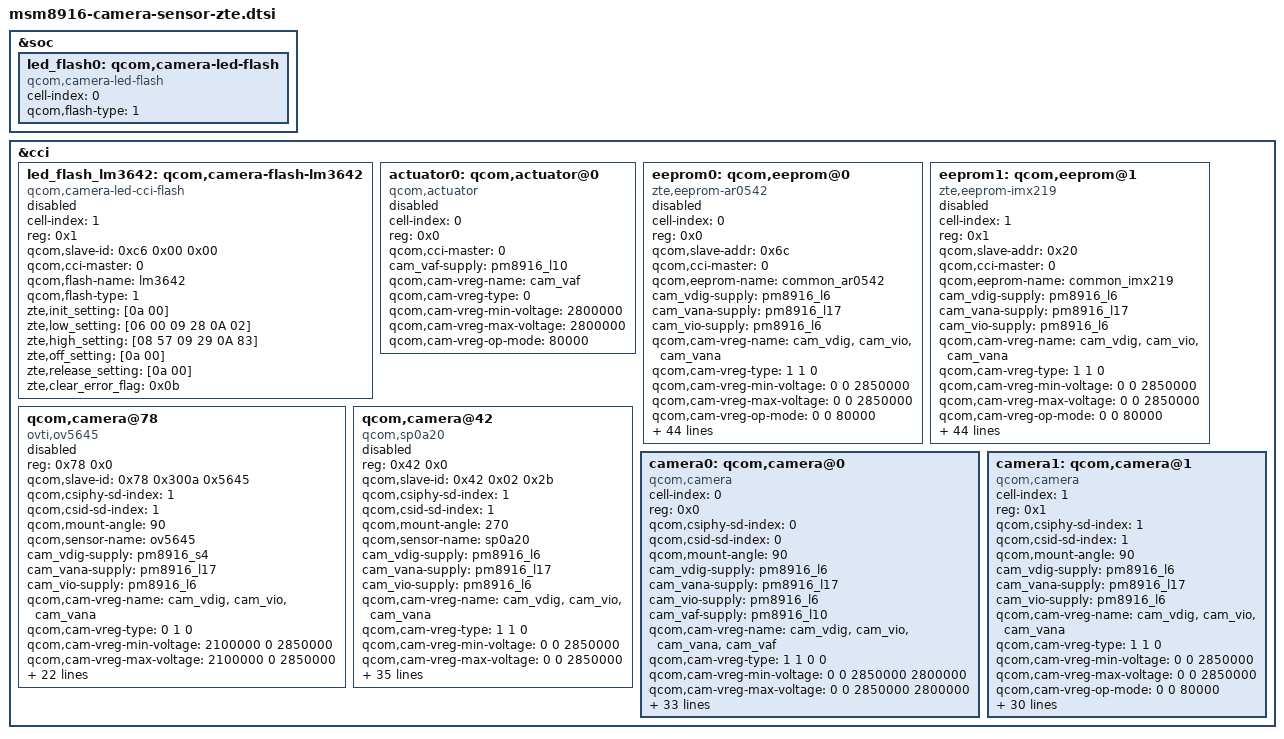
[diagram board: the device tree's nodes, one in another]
/*
 * Copyright (c) 2014, The Linux Foundation. All rights reserved.
 *
 * This program is free software; you can redistribute it and/or modify
 * it under the terms of the GNU General Public License version 2 and
 * only version 2 as published by the Free Software Foundation.
 *
 * This program is distributed in the hope that it will be useful,
 * but WITHOUT ANY WARRANTY; without even the implied warranty of
 * MERCHANTABILITY or FITNESS FOR A PARTICULAR PURPOSE.  See the
 * GNU General Public License for more details.
 */

/*
  * Added for camera sensor platform dtsi file  
  *
  * by ZTE_YCM_20140711 yi.changming 000011
  */
// --->
&soc {
	led_flash0: qcom,camera-led-flash {
		cell-index = <0>;
		compatible = "qcom,camera-led-flash";
		qcom,flash-type = <1>;
	};
};

&cci {


	led_flash_lm3642: qcom,camera-flash-lm3642 {
		cell-index = <1>;
		reg = <0x1>;
		qcom,slave-id = <0xc6 0x00 0x00>;
		compatible = "qcom,camera-led-cci-flash";
		qcom,cci-master = <0>;
		qcom,flash-name = "lm3642";
		qcom,flash-type = <1>;
		zte,init_setting = [0a 00];
		zte,low_setting = [06  00 // torch time, ramp-up time 16ms, ramp-down time 16ms
	 				      09  28   // current control, torch current 140.63mA, flash current 843.75mA
	 				      0A  02];  // enable register, torch mode, strobe pin disabled
		zte,high_setting = [08 57  // flash time, ramp time 1.024ms, time-out time 800ms
	 					09 29   // current control, torch current 140.63mA, flash current 937.5mA
	 					0A 83];  // enable register, flash mode, strobe pin disabled
		zte,off_setting = [0a 00];
		zte,release_setting = [0a 00];
		zte,clear_error_flag = <0x0b>;
		status = "disabled";
	};


	actuator0: qcom,actuator@0 {
		cell-index = <0>;
		reg = <0x0>;
		compatible = "qcom,actuator";
		qcom,cci-master = <0>;
		cam_vaf-supply = <&pm8916_l10>;
		qcom,cam-vreg-name = "cam_vaf";
		qcom,cam-vreg-type = <0>;
		qcom,cam-vreg-min-voltage = <2800000>;
		qcom,cam-vreg-max-voltage = <2800000>;
		qcom,cam-vreg-op-mode = <80000>;
		status = "disabled";
	};

/*
  * Added ar0542 eeprom device node  
  *
  * by ZTE_YCM_20140724 yi.changming 000025
  */
// --->
	eeprom0: qcom,eeprom@0 {
		compatible = "zte,eeprom-ar0542";
		cell-index = <0>;
		reg = <0x0>;
		qcom,slave-addr = <0x6c>;
		qcom,cci-master = <0>;
		qcom,eeprom-name = "common_ar0542";
		cam_vdig-supply = <&pm8916_l6>;
		cam_vana-supply = <&pm8916_l17>;
		cam_vio-supply = <&pm8916_l6>;
		qcom,cam-vreg-name = "cam_vdig", "cam_vio", "cam_vana";
		qcom,cam-vreg-type = <1 1 0 >;
		qcom,cam-vreg-min-voltage = <0 0 2850000>;
		qcom,cam-vreg-max-voltage = <0 0 2850000>;
		qcom,cam-vreg-op-mode = <0 0 80000>;
		pinctrl-names = "cam_default", "cam_suspend";
		pinctrl-0 = <&cam_sensor_mclk0_default
				     &cam_sensor_rear_default
				     &cam_sensor_power_avdd_default
				     &cam_sensor_power_iovdd_default
				     &cam_sensor_power_dvdd_rear_default
				     &cam_sensor_power_dvdd_front_default>;
		pinctrl-1 = <&cam_sensor_mclk0_sleep 
				     &cam_sensor_rear_sleep
				     &cam_sensor_power_avdd_sleep
				     &cam_sensor_power_iovdd_sleep
				     &cam_sensor_power_dvdd_rear_sleep
				     &cam_sensor_power_dvdd_front_sleep>;
		gpios = <&msm_gpio 26 0>,
			<&msm_gpio 35 0>,
			<&msm_gpio 34 0>,
			<&msm_gpio 17 0>,
			<&msm_gpio 121 0>,
			<&msm_gpio 16 0>,
			<&msm_gpio 36 0>;
		qcom,gpio-reset = <1>;
		qcom,gpio-standby = <2>;
		qcom,gpio-vio = <3>;
		qcom,gpio-vdig = <4>;
		qcom,gpio-vana = <5>;
		qcom,gpio-vdig-other = <6>;
		qcom,gpio-req-tbl-num = <0 1 2 3 4 5 6>;
		qcom,gpio-req-tbl-flags = <1 0 0 0 0 0 0>;
		qcom,gpio-req-tbl-label = "CAMIF_MCLK",
			"CAM_RESET1",
			"CAM_STANDBY",
			"CAM_VIO",
			"CAM_VDIG",
			"CAM_VANA",
			"CAM_VDIG_OTHER";
		qcom,cam-power-seq-type = "sensor_gpio",
								     "sensor_gpio",
								     "sensor_gpio",
								     "sensor_gpio",
								     "sensor_gpio",
								     "sensor_clk",
								     "sensor_gpio",
								     "sensor_gpio",
								     "sensor_i2c_mux";
		qcom,cam-power-seq-val = "sensor_gpio_reset",
								   "sensor_gpio_standby",
								    "sensor_gpio_vio",
								    "sensor_gpio_vdig",
								   "sensor_gpio_vana",
								    "sensor_cam_mclk",
								    "sensor_gpio_reset",
								   "sensor_gpio_standby",
								   "none";						 
		qcom,cam-power-seq-cfg-val = < 0 0   1 1 1 23880000  1 1 0>;
		qcom,cam-power-seq-delay =   < 0 10 0 3 3  2              3 3 0>;
		zte,num-blocks = <3>;
		zte,mem0    = <8     0x3802 2 0x0 1 0>;	//id
		zte,mem1    = <212  0x3802 2 0x0 1 0>;  //lsc
		zte,mem2    = <4     0x38d6 2 0x0 1 0>;   //wb
		clocks = <&clock_gcc clk_mclk0_clk_src>,
				<&clock_gcc clk_gcc_camss_mclk0_clk>;
		clock-names = "cam_src_clk", "cam_clk";
		status = "disabled";
		
	};
// <---

	eeprom1: qcom,eeprom@1 {
		compatible = "zte,eeprom-imx219";
		cell-index = <1>;
		reg = <0x1>;
		qcom,slave-addr = <0x20>;
		qcom,cci-master = <0>;
		qcom,eeprom-name = "common_imx219";
		cam_vdig-supply = <&pm8916_l6>;
		cam_vana-supply = <&pm8916_l17>;
		cam_vio-supply = <&pm8916_l6>;
		qcom,cam-vreg-name = "cam_vdig", "cam_vio", "cam_vana";
		qcom,cam-vreg-type = <1 1 0 >;
		qcom,cam-vreg-min-voltage = <0 0 2850000>;
		qcom,cam-vreg-max-voltage = <0 0 2850000>;
		qcom,cam-vreg-op-mode = <0 0 80000>;
		pinctrl-names = "cam_default", "cam_suspend";
		pinctrl-0 = <&cam_sensor_mclk0_default
				     &cam_sensor_rear_default
				     &cam_sensor_power_avdd_default
				     &cam_sensor_power_iovdd_default
				     &cam_sensor_power_dvdd_rear_default
				     &cam_sensor_power_dvdd_front_default>;
		pinctrl-1 = <&cam_sensor_mclk0_sleep 
				     &cam_sensor_rear_sleep
				     &cam_sensor_power_avdd_sleep
				     &cam_sensor_power_iovdd_sleep
				     &cam_sensor_power_dvdd_rear_sleep
				     &cam_sensor_power_dvdd_front_sleep>;
		gpios = <&msm_gpio 26 0>,
			<&msm_gpio 35 0>,
			<&msm_gpio 34 0>,
			<&msm_gpio 17 0>,
			<&msm_gpio 121 0>,
			<&msm_gpio 16 0>,
			<&msm_gpio 36 0>;
		qcom,gpio-reset = <1>;
		qcom,gpio-standby = <2>;
		qcom,gpio-vio = <3>;
		qcom,gpio-vdig = <4>;
		qcom,gpio-vana = <5>;
		qcom,gpio-vdig-other = <6>;
		qcom,gpio-req-tbl-num = <0 1 2 3 4 5 6>;
		qcom,gpio-req-tbl-flags = <1 0 0 0 0 0 0>;
		qcom,gpio-req-tbl-label = "CAMIF_MCLK",
			"CAM_RESET1",
			"CAM_STANDBY",
			"CAM_VIO",
			"CAM_VDIG",
			"CAM_VANA",
			"CAM_VDIG_OTHER";
		qcom,cam-power-seq-type = "sensor_gpio",
								     "sensor_gpio",
								     "sensor_gpio",
								     "sensor_gpio",
								     "sensor_gpio",
								     "sensor_clk",
								     "sensor_gpio",
								     "sensor_gpio",
								     "sensor_i2c_mux";
		qcom,cam-power-seq-val = "sensor_gpio_reset",
								   "sensor_gpio_standby",
								    "sensor_gpio_vio",
								    "sensor_gpio_vdig",
								   "sensor_gpio_vana",
								    "sensor_cam_mclk",
								    "sensor_gpio_reset",
								   "sensor_gpio_standby",
								   "none";						 
		qcom,cam-power-seq-cfg-val = < 0 0   1 1 1 23880000  1 1 0>;
		qcom,cam-power-seq-delay =   < 0 10 0 3 3  2              3 3 0>;
		zte,num-blocks = <3>;
		zte,mem0    = <24     0x3205 2 0x0 1 0>;	//id wb
		zte,mem1    = <5  0x3225 2 0x0 1 0>;  //af
		zte,mem2    = <8  0 2 0x0 1 0>;  //af
		clocks = <&clock_gcc clk_mclk0_clk_src>,
				<&clock_gcc clk_gcc_camss_mclk0_clk>;
		clock-names = "cam_src_clk", "cam_clk";
		status = "disabled";
		
	};

	qcom,camera@78 {
		compatible = "ovti,ov5645";
		reg = <0x78 0x0>;
		qcom,slave-id = <0x78 0x300a 0x5645>;
		qcom,csiphy-sd-index = <1>;
		qcom,csid-sd-index = <1>;
		qcom,mount-angle = <90>;
		qcom,sensor-name = "ov5645";
		cam_vdig-supply = <&pm8916_s4>;
		cam_vana-supply = <&pm8916_l17>;
		cam_vio-supply = <&pm8916_l6>;
		qcom,cam-vreg-name = "cam_vdig", "cam_vio", "cam_vana";
		qcom,cam-vreg-type = <0 1 0>;
		qcom,cam-vreg-min-voltage = <2100000 0 2850000>;
		qcom,cam-vreg-max-voltage = <2100000 0 2850000>;
		qcom,cam-vreg-op-mode = <200000 0 80000>;
		pinctrl-names = "cam_default", "cam_suspend";
		pinctrl-0 = <&cam_sensor_mclk1_default
				&cam_sensor_front_default>;
		pinctrl-1 = <&cam_sensor_mclk1_sleep &cam_sensor_front_sleep>;
		gpios = <&msm_gpio 27 0>,
			<&msm_gpio 28 0>,
			<&msm_gpio 33 0>;
		qcom,gpio-reset = <1>;
		qcom,gpio-standby = <2>;
		qcom,gpio-req-tbl-num = <0 1 2>;
		qcom,gpio-req-tbl-flags = <1 0 0>;
		qcom,gpio-req-tbl-label = "CAMIF_MCLK",
					"CAM_RESET",
					"CAM_STANDBY";
		qcom,gpio-set-tbl-num = <1 1>;
		qcom,gpio-set-tbl-flags = <0 2>;
		qcom,gpio-set-tbl-delay = <1000 4000>;
		qcom,csi-lane-assign = <0x4320>;
		qcom,csi-lane-mask = <0x3>;
		qcom,sensor-position = <1>;
		qcom,sensor-mode = <0>;
		qcom,cci-master = <0>;
		clocks = <&clock_gcc clk_mclk1_clk_src>,
				<&clock_gcc clk_gcc_camss_mclk1_clk>;
		clock-names = "cam_src_clk", "cam_clk";
		status = "disabled";
	};

/*
  * add sp0a20 sensor (kernel)
  * 
  *by ZTE_YCM_20141104 yi.changming 000099
  */
// --->
	qcom,camera@42 {
		compatible = "qcom,sp0a20";
		reg = <0x42 0x0>;
		qcom,slave-id = <0x42 0x02 0x2b>;
		qcom,csiphy-sd-index = <1>;
		qcom,csid-sd-index = <1>;
		qcom,mount-angle = <270>;
		qcom,sensor-name = "sp0a20";
		cam_vdig-supply = <&pm8916_l6>;
		cam_vana-supply = <&pm8916_l17>;
		cam_vio-supply = <&pm8916_l6>;
		qcom,cam-vreg-name = "cam_vdig", "cam_vio", "cam_vana";
		qcom,cam-vreg-type = <1 1 0>;
		qcom,cam-vreg-min-voltage = <0 0 2850000>;
		qcom,cam-vreg-max-voltage = <0 0 2850000>;
		qcom,cam-vreg-op-mode = <0 0 80000>;
		pinctrl-names = "cam_default", "cam_suspend";
		pinctrl-0 = <&cam_sensor_mclk1_default 
				     &cam_sensor_front_default 
				     &cam_sensor_power_avdd_default
				     &cam_sensor_power_iovdd_default
				     &cam_sensor_power_dvdd_rear_default
				     &cam_sensor_power_dvdd_front_default>;
		pinctrl-1 = <&cam_sensor_mclk1_sleep 
			            &cam_sensor_front_sleep 
				     &cam_sensor_power_avdd_sleep
				     &cam_sensor_power_iovdd_sleep
				     &cam_sensor_power_dvdd_rear_sleep
				     &cam_sensor_power_dvdd_front_sleep>;
		gpios = <&msm_gpio 27 0>,
			<&msm_gpio 28 0>,
			<&msm_gpio 33 0>,
			<&msm_gpio 17 0>,
			<&msm_gpio 36 0>,
			<&msm_gpio 16 0>,
			<&msm_gpio 121 0>;
		qcom,gpio-reset = <1>;
		qcom,gpio-standby = <2>;
		qcom,gpio-vio = <3>;
		qcom,gpio-vdig = <4>;
		qcom,gpio-vana = <5>;
		qcom,gpio-vdig-other = <6>;
		qcom,gpio-req-tbl-num = <0 1 2 3 4 5 6>;
		qcom,gpio-req-tbl-flags = <1 0 0 0 0 0 0>;
		qcom,gpio-req-tbl-label = "CAMIF_MCLK",
			"CAM_RESET",
			"CAM_STANDBY",
			"CAM_VIO",
			"CAM_VDIG",
			"CAM_VANA",
			"CAM_VDIG_OTHER";
		qcom,csi-lane-assign = <0x4320>;
		qcom,csi-lane-mask = <0x3>;
		qcom,sensor-position = <1>;
		qcom,sensor-mode = <0>;
		qcom,cci-master = <0>;
		qcom,mclk-23880000;
		clocks = <&clock_gcc clk_mclk1_clk_src>,
				<&clock_gcc clk_gcc_camss_mclk1_clk>;
		clock-names = "cam_src_clk", "cam_clk";
		status = "disabled";
	};
// <---000099
	
/*
  * add camera power gpio pinctrl for rear and front sensor 
  * fix a bug  gpio fualt
  *
  * by ZTE_YCM_20140718 yi.changming 000020
  *
  *solve that led flash device node can't light 
  *by ZTE_YCM_20140728 yi.changming 000030
  */
// --->
/**rear camera**/
camera0:qcom,camera@0 {
		cell-index = <0>;
		compatible = "qcom,camera";
		reg = <0x0>;
		qcom,csiphy-sd-index = <0>;
		qcom,csid-sd-index = <0>;
		qcom,mount-angle = <90>;
		cam_vdig-supply = <&pm8916_l6>;
		cam_vana-supply = <&pm8916_l17>;
		cam_vio-supply = <&pm8916_l6>;
		cam_vaf-supply = <&pm8916_l10>;
		qcom,cam-vreg-name = "cam_vdig", "cam_vio", "cam_vana",
							"cam_vaf";
		qcom,cam-vreg-type = <1 1 0 0>;
		qcom,cam-vreg-min-voltage = <0 0 2850000 2800000>;
		qcom,cam-vreg-max-voltage = <0 0 2850000 2800000>;
		qcom,cam-vreg-op-mode = <0 0 80000 100000>;
		pinctrl-names = "cam_default", "cam_suspend";
		pinctrl-0 = <&cam_sensor_mclk0_default
				     &cam_sensor_rear_default
				     &cam_sensor_power_avdd_default
				     &cam_sensor_power_iovdd_default
				     &cam_sensor_power_dvdd_rear_default
				     &cam_sensor_power_dvdd_front_default>;
		pinctrl-1 = <&cam_sensor_mclk0_sleep 
				     &cam_sensor_rear_sleep
				     &cam_sensor_power_avdd_sleep
				     &cam_sensor_power_iovdd_sleep
				     &cam_sensor_power_dvdd_rear_sleep
				     &cam_sensor_power_dvdd_front_sleep>;
		gpios = <&msm_gpio 26 0>,
			<&msm_gpio 35 0>,
			<&msm_gpio 34 0>,
			<&msm_gpio 17 0>,
			<&msm_gpio 121 0>,
			<&msm_gpio 16 0>,
			<&msm_gpio 36 0>;
		qcom,gpio-reset = <1>;
		qcom,gpio-standby = <2>;
		qcom,gpio-vio = <3>;
		qcom,gpio-vdig = <4>;
		qcom,gpio-vana = <5>;
		qcom,gpio-vdig-other = <6>;
		qcom,gpio-req-tbl-num = <0 1 2 3 4 5 6>;
		qcom,gpio-req-tbl-flags = <1 0 0 0 0 0 0>;
		qcom,gpio-req-tbl-label = "CAMIF_MCLK",
			"CAM_RESET1",
			"CAM_STANDBY",
			"CAM_VIO",
			"CAM_VDIG",
			"CAM_VANA",
			"CAM_VDIG_OTHER";
		qcom,sensor-position = <0>;
		qcom,sensor-mode = <0>;
		qcom,cci-master = <0>;
		qcom,mclk-23880000;
		status = "ok";
		clocks = <&clock_gcc clk_mclk0_clk_src>,
				<&clock_gcc clk_gcc_camss_mclk0_clk>;
		clock-names = "cam_src_clk", "cam_clk";
	};

/**front camera**/
camera1:qcom,camera@1 {
		cell-index = <1>;
		compatible = "qcom,camera";
		reg = <0x1>;
		qcom,csiphy-sd-index = <1>;
		qcom,csid-sd-index = <1>;
		qcom,mount-angle = <90>;
		cam_vdig-supply = <&pm8916_l6>;
		cam_vana-supply = <&pm8916_l17>;
		cam_vio-supply = <&pm8916_l6>;
		qcom,cam-vreg-name = "cam_vdig", "cam_vio", "cam_vana";
		qcom,cam-vreg-type = <1 1 0>;
		qcom,cam-vreg-min-voltage = <0 0 2850000>;
		qcom,cam-vreg-max-voltage = <0 0 2850000>;
		qcom,cam-vreg-op-mode = <0 0 80000>;
		pinctrl-names = "cam_default", "cam_suspend";
		pinctrl-0 = <&cam_sensor_mclk1_default 
				     &cam_sensor_front_default 
				     &cam_sensor_power_avdd_default
				     &cam_sensor_power_iovdd_default
				     &cam_sensor_power_dvdd_rear_default
				     &cam_sensor_power_dvdd_front_default>;
		pinctrl-1 = <&cam_sensor_mclk1_sleep 
			            &cam_sensor_front_sleep 
				     &cam_sensor_power_avdd_sleep
				     &cam_sensor_power_iovdd_sleep
				     &cam_sensor_power_dvdd_rear_sleep
				     &cam_sensor_power_dvdd_front_sleep>;
		gpios = <&msm_gpio 27 0>,
			<&msm_gpio 28 0>,
			<&msm_gpio 33 0>,
			<&msm_gpio 17 0>,
			<&msm_gpio 36 0>,
			<&msm_gpio 16 0>,
			<&msm_gpio 121 0>;
		qcom,gpio-reset = <1>;
		qcom,gpio-standby = <2>;
		qcom,gpio-vio = <3>;
		qcom,gpio-vdig = <4>;
		qcom,gpio-vana = <5>;
		qcom,gpio-vdig-other = <6>;
		qcom,gpio-req-tbl-num = <0 1 2 3 4 5 6>;
		qcom,gpio-req-tbl-flags = <1 0 0 0 0 0 0>;
		qcom,gpio-req-tbl-label = "CAMIF_MCLK",
			"CAM_RESET",
			"CAM_STANDBY",
			"CAM_VIO",
			"CAM_VDIG",
			"CAM_VANA",
			"CAM_VDIG_OTHER";
		qcom,cci-master = <0>;
		qcom,mclk-23880000;
		status = "ok";
		clocks = <&clock_gcc clk_mclk1_clk_src>,
				<&clock_gcc clk_gcc_camss_mclk1_clk>;
		clock-names = "cam_src_clk", "cam_clk";
	};
// <---

};
// <---
